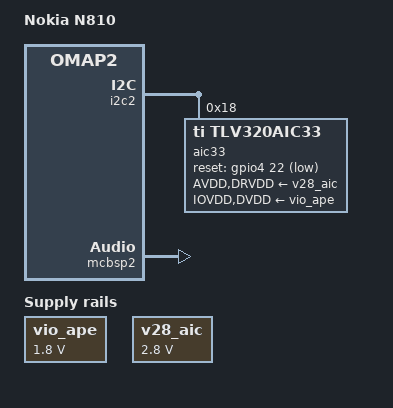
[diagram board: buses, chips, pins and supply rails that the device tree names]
/dts-v1/;
#include "omap2420-n8x0-common.dtsi"
/ {
	model = "Nokia N810";
	compatible = "nokia,n810", "nokia,n8x0", "ti,omap2420", "ti,omap2";
	vio_ape: vio_ape {
		compatible = "regulator-fixed";
		regulator-name = "vio_ape";
		regulator-min-microvolt = <1800000>;
		regulator-max-microvolt = <1800000>;
	};
	v28_aic: v28_aic {
		compatible = "regulator-fixed";
		regulator-name = "v28_aic";
		regulator-min-microvolt = <2800000>;
		regulator-max-microvolt = <2800000>;
	};
};
&omap2420_pmx {
	mcbsp2_pins: mcbsp2-pins {
		pinctrl-single,pins = <
			OMAP2420_CORE_IOPAD(0x0124, PIN_INPUT | MUX_MODE1)	 
			OMAP2420_CORE_IOPAD(0x0125, PIN_INPUT | MUX_MODE1)	 
			OMAP2420_CORE_IOPAD(0x0126, PIN_INPUT | MUX_MODE1)	 
			OMAP2420_CORE_IOPAD(0x0127, PIN_OUTPUT | MUX_MODE1)	 
		>;
	};
	aic33_pins: aic33-pins {
		pinctrl-single,pins = <
			OMAP2420_CORE_IOPAD(0x0129, PIN_OUTPUT | MUX_MODE3)	 
			OMAP2420_CORE_IOPAD(0x00e8, PIN_OUTPUT | MUX_MODE2)	 
		>;
	};
};
&i2c2 {
	aic33@18 {
		compatible = "ti,tlv320aic33";
		reg = <0x18>;
		pinctrl-names = "default";
		pinctrl-0 = <&aic33_pins>;
		reset-gpios = <&gpio4 22 GPIO_ACTIVE_LOW>;  
		ai3x-gpio-func = <
			10  
			5  
		>;
		ai3x-micbias-vg = <1>;  
		AVDD-supply = <&v28_aic>;
		DRVDD-supply = <&v28_aic>;
		IOVDD-supply = <&vio_ape>;
		DVDD-supply = <&vio_ape>;
		assigned-clocks = <&sys_clkout2_src>, <&sys_clkout2>;
		assigned-clock-parents = <&func_96m_ck>;
		assigned-clock-rates = <0>, <12000000>;
	};
};
&mcbsp2 {
	pinctrl-names = "default";
	pinctrl-0 = <&mcbsp2_pins>;
	status = "okay";
};
